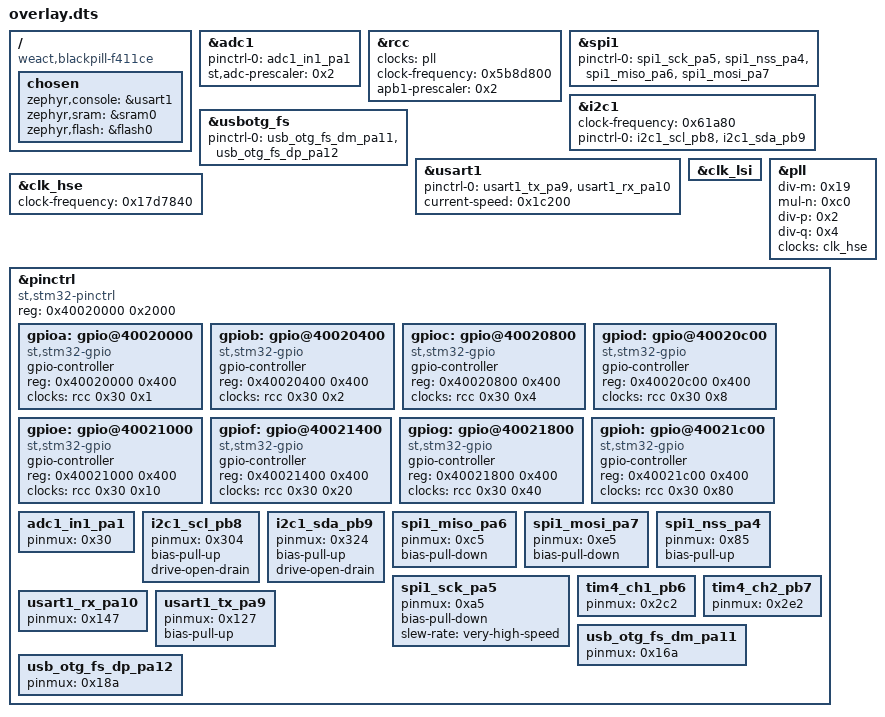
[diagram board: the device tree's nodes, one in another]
/ {
	compatible = "weact,blackpill-f411ce";
	chosen {
		zephyr,console = &usart1;
		zephyr,sram = &sram0;
		zephyr,flash = &flash0;
	};
};
&adc1{
	status = "okay";
	pinctrl-0 = < &adc1_in1_pa1 >;
	pinctrl-names = "default";
	st,adc-prescaler = < 0x2 >;
};
&rcc{
	clocks = < &pll >;
	clock-frequency = < 0x5b8d800 >;
	apb1-prescaler = < 0x2 >;
};
&spi1{
	status = "okay";
	pinctrl-0 = < &spi1_sck_pa5 &spi1_nss_pa4 &spi1_miso_pa6 &spi1_mosi_pa7 >;
	pinctrl-names = "default";
};
&i2c1{
	clock-frequency = < 0x61a80 >;
	status = "okay";
	pinctrl-0 = < &i2c1_scl_pb8 &i2c1_sda_pb9 >;
	pinctrl-names = "default";
};
&usbotg_fs{
	status = "okay";
	pinctrl-0 = < &usb_otg_fs_dm_pa11 &usb_otg_fs_dp_pa12 >;
	pinctrl-names = "default";
};
&usart1{
	status = "okay";
	pinctrl-0 = < &usart1_tx_pa9 &usart1_rx_pa10 >;
	pinctrl-names = "default";
	current-speed = < 0x1c200 >;
};
&clk_lsi{
	status = "okay";
};
&clk_hse{
	status = "okay";
	clock-frequency = < 0x17d7840 >;
};
&pll{
	status = "okay";
	div-m = < 0x19 >;
	mul-n = < 0xc0 >;
	div-p = < 0x2 >;
	div-q = < 0x4 >;
	clocks = < &clk_hse >;
};
&pinctrl{
	compatible = "st,stm32-pinctrl";
	#address-cells = < 0x1 >;
	#size-cells = < 0x1 >;
	reg = < 0x40020000 0x2000 >;
	gpioa: gpio@40020000 {
		compatible = "st,stm32-gpio";
		gpio-controller;
		#gpio-cells = < 0x2 >;
		reg = < 0x40020000 0x400 >;
		clocks = < &rcc 0x30 0x1 >;
	};
	gpiob: gpio@40020400 {
		compatible = "st,stm32-gpio";
		gpio-controller;
		#gpio-cells = < 0x2 >;
		reg = < 0x40020400 0x400 >;
		clocks = < &rcc 0x30 0x2 >;
	};
	gpioc: gpio@40020800 {
		compatible = "st,stm32-gpio";
		gpio-controller;
		#gpio-cells = < 0x2 >;
		reg = < 0x40020800 0x400 >;
		clocks = < &rcc 0x30 0x4 >;
	};
	gpiod: gpio@40020c00 {
		compatible = "st,stm32-gpio";
		gpio-controller;
		#gpio-cells = < 0x2 >;
		reg = < 0x40020c00 0x400 >;
		clocks = < &rcc 0x30 0x8 >;
	};
	gpioe: gpio@40021000 {
		compatible = "st,stm32-gpio";
		gpio-controller;
		#gpio-cells = < 0x2 >;
		reg = < 0x40021000 0x400 >;
		clocks = < &rcc 0x30 0x10 >;
	};
	gpiof: gpio@40021400 {
		compatible = "st,stm32-gpio";
		gpio-controller;
		#gpio-cells = < 0x2 >;
		reg = < 0x40021400 0x400 >;
		clocks = < &rcc 0x30 0x20 >;
	};
	gpiog: gpio@40021800 {
		compatible = "st,stm32-gpio";
		gpio-controller;
		#gpio-cells = < 0x2 >;
		reg = < 0x40021800 0x400 >;
		clocks = < &rcc 0x30 0x40 >;
	};
	gpioh: gpio@40021c00 {
		compatible = "st,stm32-gpio";
		gpio-controller;
		#gpio-cells = < 0x2 >;
		reg = < 0x40021c00 0x400 >;
		clocks = < &rcc 0x30 0x80 >;
	};
	adc1_in1_pa1: adc1_in1_pa1 {
		pinmux = < 0x30 >;
	};
	i2c1_scl_pb8: i2c1_scl_pb8 {
		pinmux = < 0x304 >;
		bias-pull-up;
		drive-open-drain;
	};
	i2c1_sda_pb9: i2c1_sda_pb9 {
		pinmux = < 0x324 >;
		bias-pull-up;
		drive-open-drain;
	};
	spi1_miso_pa6: spi1_miso_pa6 {
		pinmux = < 0xc5 >;
		bias-pull-down;
	};
	spi1_mosi_pa7: spi1_mosi_pa7 {
		pinmux = < 0xe5 >;
		bias-pull-down;
	};
	spi1_nss_pa4: spi1_nss_pa4 {
		pinmux = < 0x85 >;
		bias-pull-up;
	};
	spi1_sck_pa5: spi1_sck_pa5 {
		pinmux = < 0xa5 >;
		bias-pull-down;
		slew-rate = "very-high-speed";
	};
	tim4_ch1_pb6: tim4_ch1_pb6 {
		pinmux = < 0x2c2 >;
	};
	tim4_ch2_pb7: tim4_ch2_pb7 {
		pinmux = < 0x2e2 >;
	};
	usart1_rx_pa10: usart1_rx_pa10 {
		pinmux = < 0x147 >;
	};
	usart1_tx_pa9: usart1_tx_pa9 {
		pinmux = < 0x127 >;
		bias-pull-up;
	};
	usb_otg_fs_dm_pa11: usb_otg_fs_dm_pa11 {
		pinmux = < 0x16a >;
	};
	usb_otg_fs_dp_pa12: usb_otg_fs_dp_pa12 {
		pinmux = < 0x18a >;
	};
};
